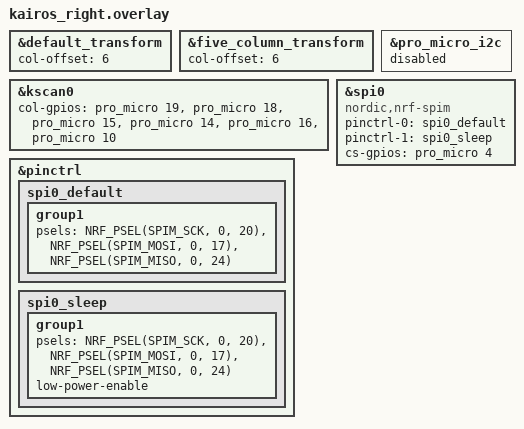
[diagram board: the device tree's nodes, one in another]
/*
 * Copyright (c) 2020 Pete Johanson
 *
 * SPDX-License-Identifier: MIT
 */

#include "kairos.dtsi"

&default_transform {
    col-offset = <6>;
};

&five_column_transform {
    col-offset = <6>;
};

&kscan0 {
    col-gpios
        = <&pro_micro 19 GPIO_ACTIVE_HIGH>
        , <&pro_micro 18 GPIO_ACTIVE_HIGH>
        , <&pro_micro 15 GPIO_ACTIVE_HIGH>
        , <&pro_micro 14 GPIO_ACTIVE_HIGH>
        , <&pro_micro 16 GPIO_ACTIVE_HIGH>
        , <&pro_micro 10 GPIO_ACTIVE_HIGH>
        ;
};

/* i2c0 and spi0 cannot be used at the same time; see also nice_view_adapter */
&pro_micro_i2c {
    status = "disabled";
};

// / {
// chosen {
//     zephyr,display = "&epd";
// };
// };

&pinctrl {
    spi0_default: spi0_default {
        group1 {
            psels = <NRF_PSEL(SPIM_SCK, 0, 20)>,
                <NRF_PSEL(SPIM_MOSI, 0, 17)>,
                <NRF_PSEL(SPIM_MISO, 0, 24)>;
        };
    };

    spi0_sleep: spi0_sleep {
        group1 {
            psels = <NRF_PSEL(SPIM_SCK, 0, 20)>,
                <NRF_PSEL(SPIM_MOSI, 0, 17)>,
                <NRF_PSEL(SPIM_MISO, 0, 24)>;
            low-power-enable;
        };
    };
};

nice_view_spi: &spi0 {
    status = "okay";
    compatible = "nordic,nrf-spim";
    pinctrl-0 = <&spi0_default>;
    pinctrl-1 = <&spi0_sleep>;
    pinctrl-names = "default", "sleep";
    cs-gpios = <&pro_micro 4 GPIO_ACTIVE_HIGH>;
};
